VERSION ""

NS_ :

BS_: 500

BU_: Vector__XXX

BO_ 160 MSG_0A0: 8 Vector__XXX
 SG_ Steering_Angle : 32|13@1+ (-0.12,0) [-720|720] "��" Vector__XXX

BO_ 168 MSG_0A8: 8 Vector__XXX
 SG_ Engine_Speed : 50|14@1+ (1,0) [0|8000] "rpm" Vector__XXX

BO_ 189 MSG_0BD: 8 Vector__XXX
 SG_ Brake_Position : 33|11@1+ (0.0625,-20) [0|100] "%" Vector__XXX

BO_ 259 MSG_103: 8 Vector__XXX
 SG_ Wheel_Speed_RL_kph : 16|12@1+ (0.1,0) [0|400] "km/h" Vector__XXX
 SG_ Wheel_Speed_RL_mph : 16|12@1+ (0.0621,0) [0|248.4] "mph" Vector__XXX
 SG_ Wheel_Speed_FL_kph : 28|12@1+ (0.1,0) [0|500] "km/h" Vector__XXX
 SG_ Wheel_Speed_FL_mph : 28|12@1+ (0.0621,0) [0|310.5] "mph" Vector__XXX
 SG_ Wheel_Speed_RR_kph : 40|12@1+ (0.1,0) [0|400] "km/h" Vector__XXX
 SG_ Wheel_Speed_RR_mph : 40|12@1+ (0.0621,0) [0|248.4] "mph" Vector__XXX
 SG_ Wheel_Speed_FR_kph : 52|12@1+ (0.1,0) [0|400] "km/h" Vector__XXX
 SG_ Wheel_Speed_FR_mph : 52|12@1+ (0.0621,0) [0|248.4] "mph" Vector__XXX

BO_ 260 MSG_104: 8 Vector__XXX
 SG_ Clutch_Position : 24|8@0+ (0.47619,-9.5238) [0|100] "%" Vector__XXX

BO_ 289 MSG_121: 8 Vector__XXX
 SG_ Accelerator_Pedal_Position : 12|8@1+ (0.4,0) [0|100] "%" Vector__XXX

BO_ 779 MSG_30B: 8 Vector__XXX
 SG_ ABS_Intervention : 0|1@1+ (1,0) [0|1] "on/off" Vector__XXX
 SG_ Handbrake : 23|1@1+ (1,0) [0|1] "on/off" Vector__XXX
 SG_ Indicated_Vehicle_Speed_kph : 48|10@1+ (0.32,0) [0|325.12] "km/h" Vector__XXX
 SG_ Indicated_Vehicle_Speed_mph : 48|10@1+ (0.19872,0) [0|201.89952] "mph" Vector__XXX

BO_ 968 MSG_3C8: 8 Vector__XXX
 SG_ Sport_Mode : 33|1@0+ (1,0) [0|1] "on/off" Vector__XXX
 SG_ Race_Mode : 35|1@0+ (1,0) [0|1] "on/off" Vector__XXX

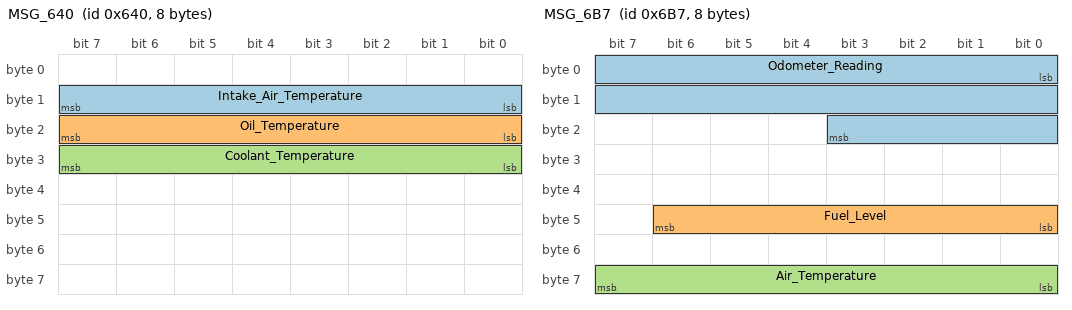
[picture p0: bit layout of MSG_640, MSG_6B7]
BO_ 1600 MSG_640: 8 Vector__XXX
 SG_ Intake_Air_Temperature : 8|8@1+ (0.75,-48) [-48|141.75] "��C" Vector__XXX
 SG_ Oil_Temperature : 16|8@1+ (1,-60) [-60|192] "��C" Vector__XXX
 SG_ Coolant_Temperature : 24|8@1+ (0.75,-48) [-48|141.75] "��C" Vector__XXX

BO_ 1719 MSG_6B7: 8 Vector__XXX
 SG_ Odometer_Reading : 0|20@1+ (1,0) [0|1048573] "km" Vector__XXX
 SG_ Fuel_Level : 40|7@1+ (1,0) [0|126] "L" Vector__XXX
 SG_ Air_Temperature : 56|8@1+ (0.5,-50) [-50|75] "��C" Vector__XXX
